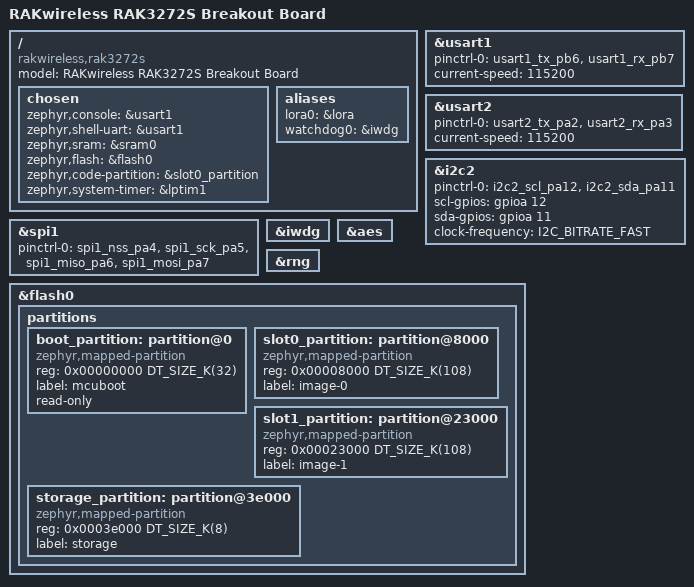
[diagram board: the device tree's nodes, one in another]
/*
 * Copyright (c) 2024 Kenneth Lu <kuohsianglu@gmail.com>
 * SPDX-License-Identifier: Apache-2.0
 */

/dts-v1/;
#include <rakwireless/rak3172.dtsi>

/ {
	compatible = "rakwireless,rak3272s";
	model = "RAKwireless RAK3272S Breakout Board";

	chosen {
		zephyr,console = &usart1;
		zephyr,shell-uart = &usart1;
		zephyr,sram = &sram0;
		zephyr,flash = &flash0;
		zephyr,code-partition = &slot0_partition;
		zephyr,system-timer = &lptim1;
	};

	aliases {
		lora0 = &lora;
		watchdog0 = &iwdg;
	};
};

&usart1 {
	pinctrl-0 = <&usart1_tx_pb6 &usart1_rx_pb7>;
	pinctrl-names = "default";
	current-speed = <115200>;
	status = "okay";
};

&usart2 {
	pinctrl-0 = <&usart2_tx_pa2 &usart2_rx_pa3>;
	pinctrl-names = "default";
	current-speed = <115200>;
	status = "okay";
};

&i2c2 {
	pinctrl-0 = <&i2c2_scl_pa12 &i2c2_sda_pa11>;
	pinctrl-names = "default";
	scl-gpios = <&gpioa 12 GPIO_ACTIVE_HIGH>;
	sda-gpios = <&gpioa 11 GPIO_ACTIVE_HIGH>;
	clock-frequency = <I2C_BITRATE_FAST>;
	status = "okay";
};

&spi1 {
	pinctrl-0 = <&spi1_nss_pa4 &spi1_sck_pa5
		     &spi1_miso_pa6 &spi1_mosi_pa7>;
	pinctrl-names = "default";
	status = "okay";
};

&iwdg {
	status = "okay";
};

&aes {
	status = "okay";
};

&rng {
	status = "okay";
};

&flash0 {
	partitions {
		ranges;
		#address-cells = <1>;
		#size-cells = <1>;

		boot_partition: partition@0 {
			compatible = "zephyr,mapped-partition";
			reg = <0x00000000 DT_SIZE_K(32)>;
			label = "mcuboot";
			read-only;
		};

		slot0_partition: partition@8000 {
			compatible = "zephyr,mapped-partition";
			reg = <0x00008000 DT_SIZE_K(108)>;
			label = "image-0";
		};

		slot1_partition: partition@23000 {
			compatible = "zephyr,mapped-partition";
			reg = <0x00023000 DT_SIZE_K(108)>;
			label = "image-1";
		};

		storage_partition: partition@3e000 {
			compatible = "zephyr,mapped-partition";
			reg = <0x0003e000 DT_SIZE_K(8)>;
			label = "storage";
		};
	};
};
